# MK10D5 register map
File version: 1.6
Registers are 8-bit, read-write, reset 0x0 unless marked. A register's access mark holds for its fields unless they carry their own. Offsets are from the block's base; [hi:lo] are bit positions; {n}, {i} and the like mark numbered series; 'fields as' and 'values as' point back to an identical list.

## TSI0 — Touch Sensing Input
Base 0x40045000; register names take the prefix TSI0_
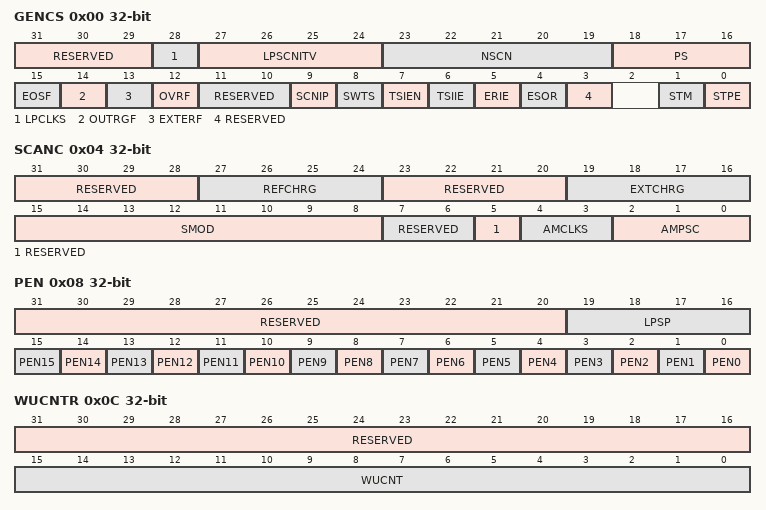
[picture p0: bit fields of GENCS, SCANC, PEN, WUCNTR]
0x00 GENCS 32-bit access per field — General Control and Status Register
  [31:29] RESERVED ro
  [28] LPCLKS rw — Low Power Mode Clock Source Selection.
    0=LPOCLK is selected to determine the scan period in low power mode; 1=VLPOSCCLK is selected to determine the scan period in low power mode
  [27:24] LPSCNITV rw — TSI Low Power Mode Scan Interval.
    0=1 ms scan interval; 1=5 ms scan interval; 2=10 ms scan interval; 3=15 ms scan interval; 4=20 ms scan interval; 5=30 ms scan interval; 6=40 ms scan interval; 7=50 ms scan interval; 8=75 ms scan interval; 9=100 ms scan interval; 10=125 ms scan interval; 11=150 ms scan interval; 12=200 ms scan interval; 13=300 ms scan interval; 14=400 ms scan interval; 15=500 ms scan interval
  [23:19] NSCN rw — Number of Consecutive Scans per Electrode electrode.
    0=Once per electrode; 1=Twice per electrode; {v}={v+1} times per electrode (v=2..31)
  [18:16] PS rw — Electrode Oscillator prescaler. .
    0=Electrode Oscillator Frequency divided by 1; 1=Electrode Oscillator Frequency divided by 2; 2=Electrode Oscillator Frequency divided by 4; 3=Electrode Oscillator Frequency divided by 8; 4=Electrode Oscillator Frequency divided by 16; 5=Electrode Oscillator Frequency divided by 32; 6=Electrode Oscillator Frequency divided by 64; 7=Electrode Oscillator Frequency divided by 128
  [15] EOSF rw — End of Scan Flag.
  [14] OUTRGF rw — Out of Range Flag.
  [13] EXTERF rw — External Electrode error occurred
    0=No fault happend on TSI electrodes; 1=Short to VDD or VSS was detected on one or more electrodes
  [12] OVRF rw — Overrun error Flag. This flag is set when a scan trigger occurs while a scan is still in progress. Write "1", when this flag is set, to clear it..
    0=No over run; 1=Over Run occurred
  [11:10] RESERVED ro
  [9] SCNIP ro — Scan In Progress status
  [8] SWTS wo — Software Trigger Start
  [7] TSIEN rw — Touch Sensing Input Module Enable
    0=TSI module is disabled; 1=TSI module is enabled
  [6] TSIIE rw — Touch Sensing Input Interrupt Module Enable
    0=Interrupt from TSI is disabled; 1=Interrupt from TSI is enabled
  [5] ERIE rw — Error Interrupt Enable
    0=Interrupt disabled for error; 1=Interrupt enabled for error
  [4] ESOR rw — End-of-Scan or Out-of-Range Interrupt select
    0=Out-of-Range interrupt is allowed; 1=End-of-Scan interrupt is allowed
  [3] RESERVED ro
  [1] STM rw — Scan Trigger Mode. This bit-field can only be changed if the TSI module is disabled (TSIEN bit = 0).
    0=Software trigger scan; 1=Periodical Scan
  [0] STPE rw
    0=Disable TSI when MCU goes into low power modes; 1=Allows TSI to continue running in all low power modes
0x04 SCANC 32-bit access per field — SCAN Control Register
  [31:28] RESERVED ro
  [27:24] REFCHRG rw — Ref OSC Charge Current select
    0=2 uA charge current; 1=4 uA charge current; 2=6 uA charge current; 3=8 uA charge current; 4=10 uA charge current; 5=12 uA charge current; 6=14 uA charge current; 7=16 uA charge current; 8=18 uA charge current; 9=20 uA charge current; 10=22 uA charge current; 11=24 uA charge current; 12=26 uA charge current; 13=28 uA charge current; 14=30 uA charge current; 15=32 uA charge current
  [23:20] RESERVED ro
  [19:16] EXTCHRG rw — External OSC Charge Current select
    values as REFCHRG
  [15:8] SMOD rw — Scan Module
    0=Continue Scan
  [7:6] RESERVED ro
  [5] RESERVED ro
  [4:3] AMCLKS rw — Active Mode Clock Source
    0=LPOSCCLK; 1=MCGIRCLK; 2=OSCERCLK; 3=Not valid
  [2:0] AMPSC rw — Active Mode Prescaler
    0=Input Clock Source divided by 1; 1=Input Clock Source divided by 2; 2=Input Clock Source divided by 4; 3=Input Clock Source divided by 8; 4=Input Clock Source divided by 16; 5=Input Clock Source divided by 32; 6=Input Clock Source divided by 64; 7=Input Clock Source divided by 128
0x08 PEN 32-bit access per field — Pin Enable Register
  [31:20] RESERVED ro
  [19:16] LPSP rw — Low Power Scan Pin
    {v}=TSI_IN[{v}] is active in low power mode (v=0..15)
  [n] PEN{n} rw (n=0..15) — Touch Sensing Input Pin Enable Register {n}
    0=The corresponding pin is not used by TSI; 1=The corresponding pin is used by TSI
0x0C WUCNTR 32-bit ro — Wake-Up Channel Counter Register
  [31:16] RESERVED
  [15:0] WUCNT — TouchSensing wake-up Channel 16bit counter value
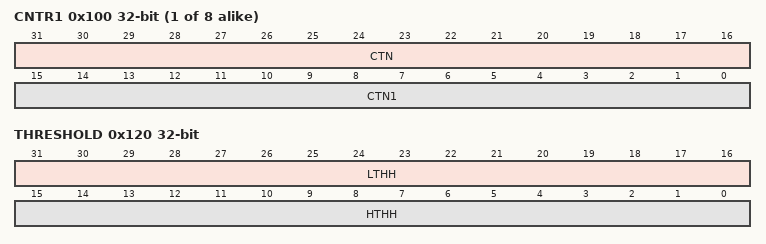
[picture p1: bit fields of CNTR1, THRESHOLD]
0x100 CNTR{x} (x=1,3,5,7,9,11,13,15; step 0x4) 32-bit ro — Counter Register
  [31:16] CTN — TouchSensing Channel n 16-bit counter value
  [15:0] CTN1 — TouchSensing Channel n-1 16-bit counter value
0x120 THRESHOLD 32-bit — Low Power Channel Threshold Register
  [31:16] LTHH — Touch Sensing Channel Low Threshold value
  [15:0] HTHH — Touch Sensing Channel High Threshold value
